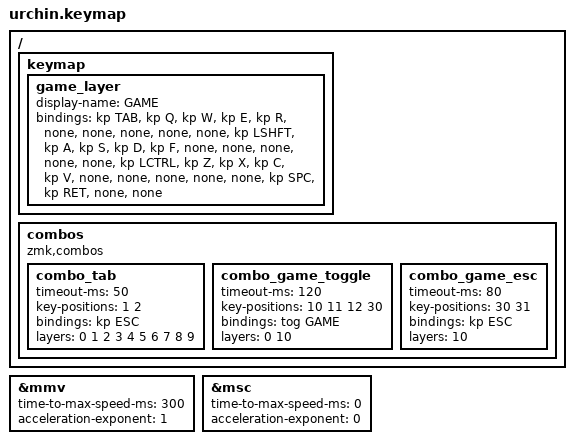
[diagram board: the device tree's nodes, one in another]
// Copyright 2023 Manna Harbour
// https://github.com/manna-harbour/miryoku

#define ZMK_POINTING_DEFAULT_MOVE_VAL 1200
#define ZMK_POINTING_DEFAULT_SCRL_VAL 1
#define GAME 10

#include "../miryoku/custom_config.h"
#include "../miryoku/mapping/34/ferris.h"
#include "../miryoku/miryoku.dtsi"

&mmv {
    time-to-max-speed-ms = <300>;
    acceleration-exponent = <1>;
};

&msc {
    time-to-max-speed-ms = <0>;
    acceleration-exponent = <0>;
};

/ {
    keymap {
        game_layer {
            display-name = "GAME";
            bindings = <
                &kp TAB   &kp Q    &kp W    &kp E    &kp R         &none &none &none &none &none
                &kp LSHFT &kp A    &kp S    &kp D    &kp F         &none &none &none &none &none
                &kp LCTRL &kp Z    &kp X    &kp C    &kp V         &none &none &none &none &none
                                   &kp SPC  &kp RET                &none &none
            >;
        };
    };

    combos {
        compatible = "zmk,combos";
        combo_tab {
            timeout-ms = <50>;
            key-positions = <1 2>;
            bindings = <&kp ESC>;
            layers = <0 1 2 3 4 5 6 7 8 9>;
        };

        combo_game_toggle {
            timeout-ms = <120>;
            key-positions = <10 11 12 30>;
            bindings = <&tog GAME>;
            layers = <0 10>;
        };

        combo_game_esc {
            timeout-ms = <80>;
            key-positions = <30 31>;
            bindings = <&kp ESC>;
            layers = <10>;
        };
    };
};
